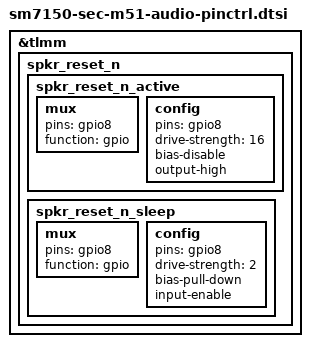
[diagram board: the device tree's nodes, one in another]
&tlmm {
	/* WSA speaker reset pins */
	spkr_reset_n {
		spkr_reset_n_active: spkr_reset_n_active {
			mux {
				pins = "gpio8";
				function = "gpio";
			};

			config {
				pins = "gpio8";
				drive-strength = <16>;   /* 16 mA */
				bias-disable;
				output-high;
			};
		};

		spkr_reset_n_sleep: spkr_reset_n_sleep {
			mux {
				pins = "gpio8";
				function = "gpio";
			};

			config {
				pins = "gpio8";
				drive-strength = <2>;   /* 2 mA */
				bias-pull-down;
				input-enable;
			};
		};
	};
};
